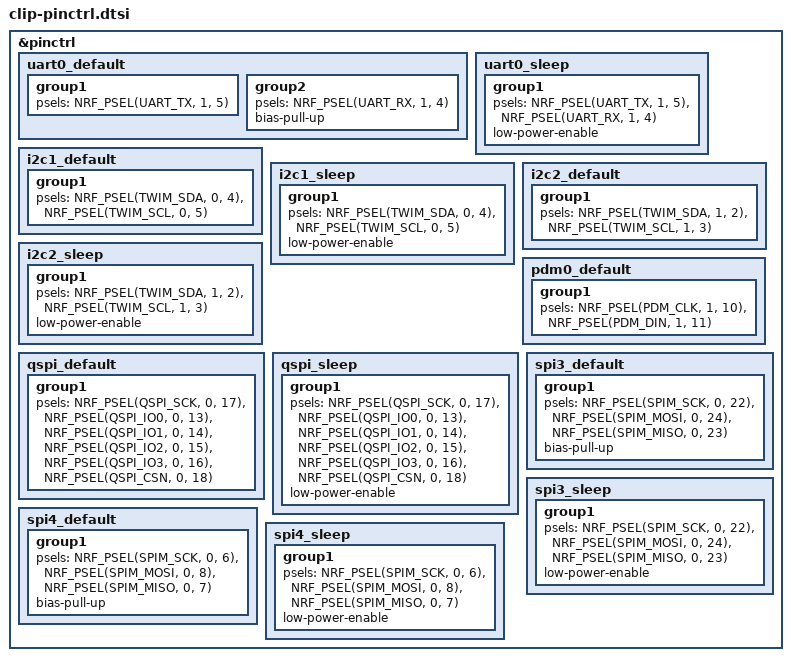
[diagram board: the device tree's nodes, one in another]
&pinctrl {
	uart0_default: uart0_default {
		group1 {
			psels = <NRF_PSEL(UART_TX, 1, 5)>;
		};
		group2 {
			psels = <NRF_PSEL(UART_RX, 1, 4)>;
			bias-pull-up;
		};
	};

	uart0_sleep: uart0_sleep {
		group1 {
			psels = <NRF_PSEL(UART_TX, 1, 5)>,
				<NRF_PSEL(UART_RX, 1, 4)>;
			low-power-enable;
		};
	};

	
	i2c1_default: i2c1_default {
		group1 {
			psels = <NRF_PSEL(TWIM_SDA, 0, 4)>,
				<NRF_PSEL(TWIM_SCL, 0, 5)>;
		};
	};

	i2c1_sleep: i2c1_sleep {
		group1 {
			psels = <NRF_PSEL(TWIM_SDA, 0, 4)>,
				<NRF_PSEL(TWIM_SCL, 0, 5)>;
			low-power-enable;
		};
	};

	i2c2_default: i2c2_default {
		group1 {
			psels = <NRF_PSEL(TWIM_SDA, 1, 2)>,
				<NRF_PSEL(TWIM_SCL, 1, 3)>;
		};
	};

	i2c2_sleep: i2c2_sleep {
		group1 {
			psels = <NRF_PSEL(TWIM_SDA, 1, 2)>,
				<NRF_PSEL(TWIM_SCL, 1, 3)>;
			low-power-enable;
		};
	};
	
	pdm0_default: pdm0_default {
		group1 {
			psels = <NRF_PSEL(PDM_CLK, 1, 10)>,
				<NRF_PSEL(PDM_DIN, 1, 11)>;
		};
	};

	qspi_default: qspi_default {
		group1 {
			psels = <NRF_PSEL(QSPI_SCK, 0, 17)>,
				<NRF_PSEL(QSPI_IO0, 0, 13)>,
				<NRF_PSEL(QSPI_IO1, 0, 14)>,
				<NRF_PSEL(QSPI_IO2, 0, 15)>,
				<NRF_PSEL(QSPI_IO3, 0, 16)>,
				<NRF_PSEL(QSPI_CSN, 0, 18)>;
		};
	};

	qspi_sleep: qspi_sleep {
		group1 {
			psels = <NRF_PSEL(QSPI_SCK, 0, 17)>,
				<NRF_PSEL(QSPI_IO0, 0, 13)>,
				<NRF_PSEL(QSPI_IO1, 0, 14)>,
				<NRF_PSEL(QSPI_IO2, 0, 15)>,
				<NRF_PSEL(QSPI_IO3, 0, 16)>,
				<NRF_PSEL(QSPI_CSN, 0, 18)>;
			low-power-enable;
		};
	};

	spi3_default: spi3_default {
		group1 {
			psels = <NRF_PSEL(SPIM_SCK, 0, 22)>,
				<NRF_PSEL(SPIM_MOSI, 0, 24)>,
				<NRF_PSEL(SPIM_MISO, 0, 23)>;
			bias-pull-up;
		};
	};

	spi3_sleep: spi3_sleep {
		group1 {
			psels = <NRF_PSEL(SPIM_SCK, 0, 22)>,
				<NRF_PSEL(SPIM_MOSI, 0, 24)>,
				<NRF_PSEL(SPIM_MISO, 0, 23)>;
			low-power-enable;
		};
	};
	spi4_default: spi4_default {
		group1 {
			psels = <NRF_PSEL(SPIM_SCK, 0, 6)>,
				<NRF_PSEL(SPIM_MOSI, 0, 8)>,
				<NRF_PSEL(SPIM_MISO, 0, 7)>;
			bias-pull-up;
		};
	};

	spi4_sleep: spi4_sleep {
		group1 {
			psels = <NRF_PSEL(SPIM_SCK, 0, 6)>,
				<NRF_PSEL(SPIM_MOSI, 0, 8)>,
				<NRF_PSEL(SPIM_MISO, 0, 7)>;
			low-power-enable;
		};
	};
};
